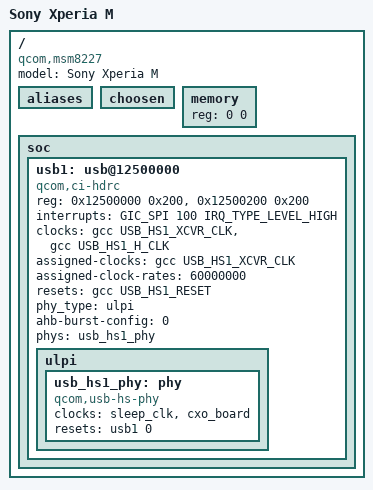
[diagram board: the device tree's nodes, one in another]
// SPDX-License-Identifier: GPL-2.0
/*
 * Copyright (C) 2019 Pavel Dubrova <pashadubrova@gmail.com>
 */

 /dts-v1/;

#include <dt-bindings/reset/qcom,gcc-msm8960.h>
#include "qcom-msm8960.dtsi"

/ {
	model = "Sony Xperia M";
	compatible = "qcom,msm8227";

	aliases { };

	choosen { };

	memory {
		device_type = "memory";
		/* We expect the bootloader to fill in the reg */
		reg = <0 0>;
	};

	soc {
		usb1: usb@12500000 {
			compatible = "qcom,ci-hdrc";
			reg = <0x12500000 0x200>,
			      <0x12500200 0x200>;
			interrupts = <GIC_SPI 100 IRQ_TYPE_LEVEL_HIGH>;
			clocks = <&gcc USB_HS1_XCVR_CLK>,
					 <&gcc USB_HS1_H_CLK>;
			clock-names = "core", "iface";
			assigned-clocks = <&gcc USB_HS1_XCVR_CLK>;
			assigned-clock-rates = <60000000>;
			resets = <&gcc USB_HS1_RESET>;
			reset-names = "core";
			phy_type = "ulpi";
			ahb-burst-config = <0>;
			phys = <&usb_hs1_phy>;
			phy-names = "usb-phy";
			#reset-cells = <1>;
			status = "okay";

			ulpi {
				usb_hs1_phy: phy {
					compatible = "qcom,usb-hs-phy";
					clocks = <&sleep_clk>, <&cxo_board>;
					clock-names = "sleep", "ref";
					resets = <&usb1 0>;
					reset-names = "por";
					#phy-cells = <0>;
				};
			};
		};
	};
 };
